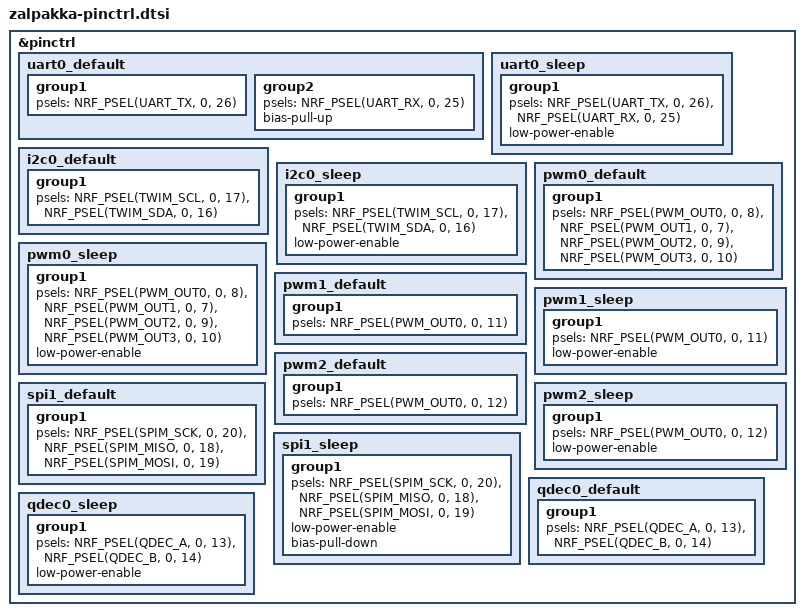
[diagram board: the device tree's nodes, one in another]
&pinctrl {
	uart0_default: uart0_default {
		group1 {
			psels = <NRF_PSEL(UART_TX, 0, 26)>;
		};
		group2 {
			psels = <NRF_PSEL(UART_RX, 0, 25)>;
			bias-pull-up;
		};
	};

	uart0_sleep: uart0_sleep {
		group1 {
			psels = <NRF_PSEL(UART_TX, 0, 26)>,
				<NRF_PSEL(UART_RX, 0, 25)>;
			low-power-enable;
		};
	};

	i2c0_default: i2c0_default {
		group1 {
			psels = <NRF_PSEL(TWIM_SCL, 0, 17)>,
				<NRF_PSEL(TWIM_SDA, 0, 16)>;
		};
	};

	i2c0_sleep: i2c0_sleep {
		group1 {
			psels = <NRF_PSEL(TWIM_SCL, 0, 17)>,
				<NRF_PSEL(TWIM_SDA, 0, 16)>;
			low-power-enable;
		};
	};

	pwm0_default: pwm0_default {
		group1 {
			psels = <NRF_PSEL(PWM_OUT0, 0, 8)>,
				<NRF_PSEL(PWM_OUT1, 0, 7)>,
				<NRF_PSEL(PWM_OUT2, 0, 9)>,
				<NRF_PSEL(PWM_OUT3, 0, 10)>;
		};
	};

	pwm0_sleep: pwm0_sleep {
		group1 {
			psels = <NRF_PSEL(PWM_OUT0, 0, 8)>,
				<NRF_PSEL(PWM_OUT1, 0, 7)>,
				<NRF_PSEL(PWM_OUT2, 0, 9)>,
				<NRF_PSEL(PWM_OUT3, 0, 10)>;
			low-power-enable;
		};
	};

	pwm1_default: pwm1_default {
		group1 {
			psels = <NRF_PSEL(PWM_OUT0, 0, 11)>;
		};
	};

	pwm1_sleep: pwm1_sleep {
		group1 {
			psels = <NRF_PSEL(PWM_OUT0, 0, 11)>;
			low-power-enable;
		};
	};

	pwm2_default: pwm2_default {
		group1 {
			psels = <NRF_PSEL(PWM_OUT0, 0, 12)>;
		};
	};

	pwm2_sleep: pwm2_sleep {
		group1 {
			psels = <NRF_PSEL(PWM_OUT0, 0, 12)>;
			low-power-enable;
		};
	};

	spi1_default: spi1_default {
		group1 {
			psels = <NRF_PSEL(SPIM_SCK, 0, 20)>,
				<NRF_PSEL(SPIM_MISO, 0, 18)>,
				<NRF_PSEL(SPIM_MOSI, 0, 19)>;
		};
	};

	spi1_sleep: spi1_sleep {
		group1 {
			psels = <NRF_PSEL(SPIM_SCK, 0, 20)>,
				<NRF_PSEL(SPIM_MISO, 0, 18)>,
				<NRF_PSEL(SPIM_MOSI, 0, 19)>;
			low-power-enable;
			bias-pull-down;
		};
	};

	qdec0_default: qdec0_default {
		group1 {
			psels = <NRF_PSEL(QDEC_A, 0, 13)>,
				<NRF_PSEL(QDEC_B, 0, 14)>;
		};
	};

	qdec0_sleep: qdec0_sleep {
		group1 {
			psels = <NRF_PSEL(QDEC_A, 0, 13)>,
				<NRF_PSEL(QDEC_B, 0, 14)>;
			low-power-enable;
		};
	};
};
